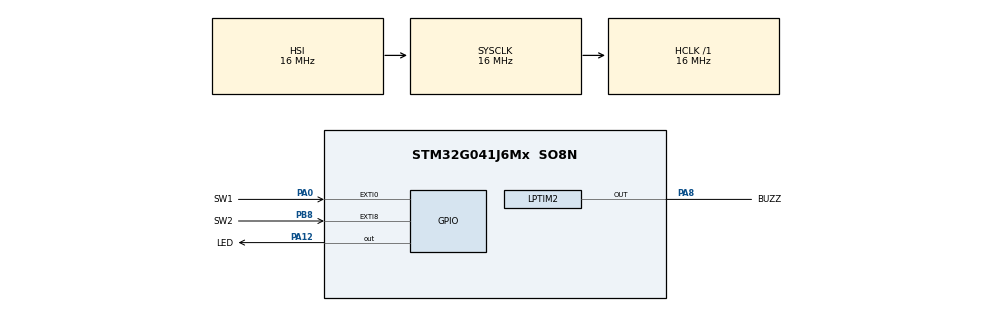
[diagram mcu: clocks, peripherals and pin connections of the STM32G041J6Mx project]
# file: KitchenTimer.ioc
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LPTIM1.ClockPrescaler=LPTIM_PRESCALER_DIV128
Mcu.Family=STM32G0
Mcu.Name=STM32G041J6Mx
Mcu.Package=SO8N
NVIC.EXTI0_1_IRQn=true\:0\:0\:false\:false\:true\:true\:true\:true
NVIC.EXTI4_15_IRQn=true\:0\:0\:false\:false\:true\:true\:true\:true
NVIC.LPTIM1_IRQn=true\:0\:0\:false\:false\:true\:true\:true\:true
PA0.GPIO_Label=SW1
PA0.GPIO_ModeDefaultEXTI=GPIO_MODE_IT_FALLING
PA0.GPIO_PuPd=GPIO_PULLUP
PA0.Signal=GPXTI0
PA12\ [PA10].GPIO_Label=LED
PA12\ [PA10].PinState=GPIO_PIN_SET
PA12\ [PA10].Signal=GPIO_Output
PA13.Mode=Serial_Wire
PA13.Signal=SYS_SWDIO
PA14-BOOT0.Mode=Serial_Wire
PA14-BOOT0.Signal=SYS_SWCLK
PA14-BOOT0__PA15__PB5__PB6.StandardMode=true
PA8.GPIO_Label=BUZZ
PA8.Mode=WaveformGeneration
PA8.Signal=LPTIM2_OUT
PB0__PB1__PA8__PA11\ [PA9].StandardMode=true
PB8.GPIO_Label=SW2
PB8.GPIO_ModeDefaultEXTI=GPIO_MODE_IT_FALLING
PB8.GPIO_PuPd=GPIO_PULLUP
PB8.Signal=GPXTI8
PC14-OSC32_IN\ (PC14)__PB7__PB8__PB9.StandardMode=true
PF2\ -\ NRST__PA0__PA1__PA2.StandardMode=true
ProjectManager.HeapSize=0x200
ProjectManager.StackSize=0x400
ProjectManager.TargetToolchain=STM32CubeIDE
RCC.ADCFreq_Value=16000000
RCC.AHBFreq_Value=16000000
RCC.CortexFreq_Value=16000000
RCC.EXTERNAL_CLOCK_VALUE=12288000
RCC.HCLKFreq_Value=16000000
RCC.HSE_VALUE=8000000
RCC.HSI_VALUE=16000000
RCC.LPTIM1CLockSelection=RCC_LPTIM1CLKSOURCE_LSI
RCC.LPTIM2CLockSelection=RCC_LPTIM2CLKSOURCE_LSI
RCC.LSE_VALUE=32768
RCC.SYSCLKFreq_VALUE=16000000
RCC.VCOOutputFreq_Value=128000000
VP_LPTIM1_VS_LPTIM_counterModeInternalClock.Mode=Counts__internal_clock_event_00
VP_LPTIM2_VS_LPTIM_counterModeInternalClock.Mode=Counts__internal_clock_event_00
board=custom

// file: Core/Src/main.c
/* USER CODE BEGIN Header */
/**
  ******************************************************************************
  * @file           : main.c
  * @brief          : Main program body
  ******************************************************************************
  * @attention
  *
  * Copyright (c) 2024 STMicroelectronics.
  * All rights reserved.
  *
  * This software is licensed under terms that can be found in the LICENSE file
  * in the root directory of this software component.
  * If no LICENSE file comes with this software, it is provided AS-IS.
  *
  ******************************************************************************
  */
/* USER CODE END Header */
#include "main.h"

LPTIM_HandleTypeDef hlptim1;
LPTIM_HandleTypeDef hlptim2;

void SystemClock_Config(void);
static void MX_GPIO_Init(void);
static void MX_LPTIM1_Init(void);
static void MX_LPTIM2_Init(void);
/* USER CODE BEGIN PFP */
extern void main_task(void);
/* USER CODE END PFP */

/* USER CODE BEGIN 0 */
/** */

/* USER CODE END 0 */

int main(void)
{

  /* MCU Configuration--------------------------------------------------------*/

  /* Reset of all peripherals, Initializes the Flash interface and the Systick. */
  HAL_Init();

  /* Configure the system clock */
  SystemClock_Config();

  /* Initialize all configured peripherals */
  MX_GPIO_Init();
  MX_LPTIM1_Init();
  MX_LPTIM2_Init();
  /* USER CODE BEGIN 2 */
  main_task();
  /* USER CODE END 2 */

  /* Infinite loop */
  while (1)
  {

  }
}

void SystemClock_Config(void)
{
  RCC_OscInitTypeDef RCC_OscInitStruct = {0};
  RCC_ClkInitTypeDef RCC_ClkInitStruct = {0};

  /** Configure the main internal regulator output voltage
  */
  HAL_PWREx_ControlVoltageScaling(PWR_REGULATOR_VOLTAGE_SCALE1);

  /** Initializes the RCC Oscillators according to the specified parameters
  * in the RCC_OscInitTypeDef structure.
  */
  RCC_OscInitStruct.OscillatorType = RCC_OSCILLATORTYPE_HSI|RCC_OSCILLATORTYPE_LSI;
  RCC_OscInitStruct.HSIState = RCC_HSI_ON;
  RCC_OscInitStruct.HSIDiv = RCC_HSI_DIV1;
  RCC_OscInitStruct.HSICalibrationValue = RCC_HSICALIBRATION_DEFAULT;
  RCC_OscInitStruct.LSIState = RCC_LSI_ON;
  RCC_OscInitStruct.PLL.PLLState = RCC_PLL_NONE;
  if (HAL_RCC_OscConfig(&RCC_OscInitStruct) != HAL_OK)
  {
    Error_Handler();
  }

  /** Initializes the CPU, AHB and APB buses clocks
  */
  RCC_ClkInitStruct.ClockType = RCC_CLOCKTYPE_HCLK|RCC_CLOCKTYPE_SYSCLK
                              |RCC_CLOCKTYPE_PCLK1;
  RCC_ClkInitStruct.SYSCLKSource = RCC_SYSCLKSOURCE_HSI;
  RCC_ClkInitStruct.AHBCLKDivider = RCC_SYSCLK_DIV1;
  RCC_ClkInitStruct.APB1CLKDivider = RCC_HCLK_DIV1;

  if (HAL_RCC_ClockConfig(&RCC_ClkInitStruct, FLASH_LATENCY_0) != HAL_OK)
  {
    Error_Handler();
  }
}

static void MX_LPTIM1_Init(void)
{

  hlptim1.Instance = LPTIM1;
  hlptim1.Init.Clock.Source = LPTIM_CLOCKSOURCE_APBCLOCK_LPOSC;
  hlptim1.Init.Clock.Prescaler = LPTIM_PRESCALER_DIV128;
  hlptim1.Init.Trigger.Source = LPTIM_TRIGSOURCE_SOFTWARE;
  hlptim1.Init.OutputPolarity = LPTIM_OUTPUTPOLARITY_HIGH;
  hlptim1.Init.UpdateMode = LPTIM_UPDATE_IMMEDIATE;
  hlptim1.Init.CounterSource = LPTIM_COUNTERSOURCE_INTERNAL;
  hlptim1.Init.Input1Source = LPTIM_INPUT1SOURCE_GPIO;
  hlptim1.Init.Input2Source = LPTIM_INPUT2SOURCE_GPIO;
  if (HAL_LPTIM_Init(&hlptim1) != HAL_OK)
  {
    Error_Handler();
  }

}

static void MX_LPTIM2_Init(void)
{

  hlptim2.Instance = LPTIM2;
  hlptim2.Init.Clock.Source = LPTIM_CLOCKSOURCE_APBCLOCK_LPOSC;
  hlptim2.Init.Clock.Prescaler = LPTIM_PRESCALER_DIV1;
  hlptim2.Init.Trigger.Source = LPTIM_TRIGSOURCE_SOFTWARE;
  hlptim2.Init.OutputPolarity = LPTIM_OUTPUTPOLARITY_HIGH;
  hlptim2.Init.UpdateMode = LPTIM_UPDATE_IMMEDIATE;
  hlptim2.Init.CounterSource = LPTIM_COUNTERSOURCE_INTERNAL;
  hlptim2.Init.Input1Source = LPTIM_INPUT1SOURCE_GPIO;
  if (HAL_LPTIM_Init(&hlptim2) != HAL_OK)
  {
    Error_Handler();
  }

}

static void MX_GPIO_Init(void)
{
  GPIO_InitTypeDef GPIO_InitStruct = {0};

  /* GPIO Ports Clock Enable */
  __HAL_RCC_GPIOB_CLK_ENABLE();
  __HAL_RCC_GPIOA_CLK_ENABLE();

  /*Configure GPIO pin Output Level */
  HAL_GPIO_WritePin(LED_GPIO_Port, LED_Pin, GPIO_PIN_SET);

  /*Configure GPIO pin : SW2_Pin */
  GPIO_InitStruct.Pin = SW2_Pin;
  GPIO_InitStruct.Mode = GPIO_MODE_IT_FALLING;
  GPIO_InitStruct.Pull = GPIO_PULLUP;
  HAL_GPIO_Init(SW2_GPIO_Port, &GPIO_InitStruct);

  /*Configure GPIO pin : SW1_Pin */
  GPIO_InitStruct.Pin = SW1_Pin;
  GPIO_InitStruct.Mode = GPIO_MODE_IT_FALLING;
  GPIO_InitStruct.Pull = GPIO_PULLUP;
  HAL_GPIO_Init(SW1_GPIO_Port, &GPIO_InitStruct);

  /*Configure GPIO pin : LED_Pin */
  GPIO_InitStruct.Pin = LED_Pin;
  GPIO_InitStruct.Mode = GPIO_MODE_OUTPUT_PP;
  GPIO_InitStruct.Pull = GPIO_NOPULL;
  GPIO_InitStruct.Speed = GPIO_SPEED_FREQ_LOW;
  HAL_GPIO_Init(LED_GPIO_Port, &GPIO_InitStruct);

  /* EXTI interrupt init*/
  HAL_NVIC_SetPriority(EXTI0_1_IRQn, 0, 0);
  HAL_NVIC_EnableIRQ(EXTI0_1_IRQn);

  HAL_NVIC_SetPriority(EXTI4_15_IRQn, 0, 0);
  HAL_NVIC_EnableIRQ(EXTI4_15_IRQn);

}

void Error_Handler(void)
{
  __disable_irq();
  while (1)
  {
  }
}
